# CY8C5888LTI_LP097 register map
File version: 0.1
CY8C58LP
Registers are 8-bit, read-write, no defined reset value unless marked. A register's access mark holds for its fields unless they carry their own. Offsets are from the block's base; lines under a group give offsets from that group; [hi:lo] are bit positions; {n}, {i} and the like mark numbered series; 'fields as' and 'values as' point back to an identical list; <NAME> marks a mode.

## Memory map
0x00000000 PWM
0x00000000 PWM_1

## PWM
Base 0x00000000
0x4000642E PWM_COMPARE_Reg 16-bit — UDB.D0 - Assigned Compare Value
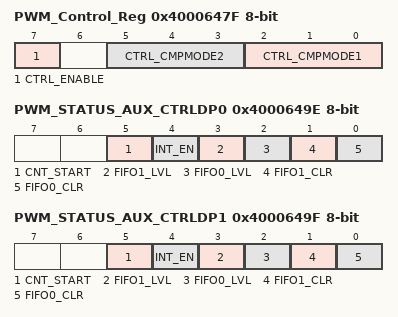
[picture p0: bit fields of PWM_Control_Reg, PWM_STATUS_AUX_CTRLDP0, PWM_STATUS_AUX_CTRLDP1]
0x4000647F PWM_Control_Reg — UDB Control Register - Assigned Control Register Value
  [7] CTRL_ENABLE — Enable the PWM
  [5:3] CTRL_CMPMODE2 — Compare mode 2
  [2:0] CTRL_CMPMODE1 — Compare mode 1
0x4000649E PWM_STATUS_AUX_CTRLDP0 — UDB Auxilliary Control Register
  [5] CNT_START — FIFO0 clear
    0=E_CNT_START0 (Disable counter); 1=E_CNT_START1 (Enable counter)
  [4] INT_EN
    0=E_INT_EN0 (Interrupt disabled); 1=E_INT_EN1 (Interrupt enabled)
  [3] FIFO1_LVL — FIFO level
    0=E_FIFO_LVL_0 (FIFO LVL: input mode: FIFO not full; output mode: FIFO not empty); 1=E_FIFO_LVL_1 (FIFO LVL: input mode: FIFO at least 1/2 empty; output mode: FIFO at least 1/2 full)
  [2] FIFO0_LVL — FIFO level
    values as FIFO1_LVL
  [1] FIFO1_CLR — FIFO1 clear
    0=E_FIFO_CLR_0 (Normal FIFO operation); 1=E_FIFO_CLR_1 (Clear FIFO state)
  [0] FIFO0_CLR — FIFO0 clear
    values as FIFO1_CLR
0x4000649F PWM_STATUS_AUX_CTRLDP1 — UDB Auxilliary Control Register
  fields as PWM_STATUS_AUX_CTRLDP0

## PWM_1
Base 0x00000000
0x4000642C PWM_1_COMPARE_Reg 16-bit — UDB.D0 - Assigned Compare Value
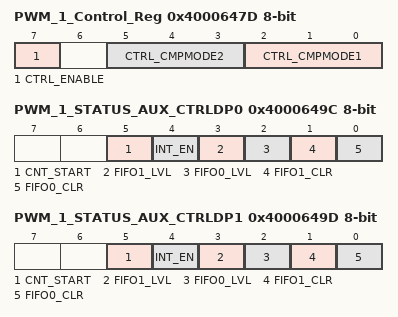
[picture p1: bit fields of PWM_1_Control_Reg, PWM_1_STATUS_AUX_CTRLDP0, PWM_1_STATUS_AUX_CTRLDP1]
0x4000647D PWM_1_Control_Reg — UDB Control Register - Assigned Control Register Value
  [7] CTRL_ENABLE — Enable the PWM
  [5:3] CTRL_CMPMODE2 — Compare mode 2
  [2:0] CTRL_CMPMODE1 — Compare mode 1
0x4000649C PWM_1_STATUS_AUX_CTRLDP0 — UDB Auxilliary Control Register
  fields as PWM.PWM_STATUS_AUX_CTRLDP0
0x4000649D PWM_1_STATUS_AUX_CTRLDP1 — UDB Auxilliary Control Register
  fields as PWM.PWM_STATUS_AUX_CTRLDP0
